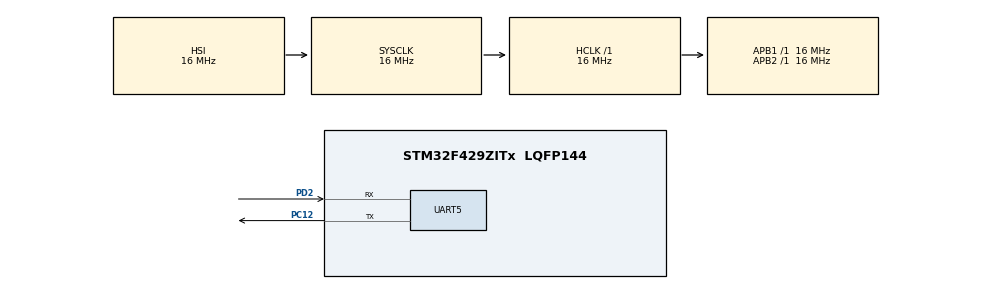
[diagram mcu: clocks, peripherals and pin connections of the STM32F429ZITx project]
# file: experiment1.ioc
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Mcu.Family=STM32F4
RCC.CortexFreq_Value=16000000
PC12.Signal=UART5_TX
PC14/OSC32_IN.Mode=LSE-External-Oscillator
UART5.VirtualMode=Asynchronous
ProjectManager.StackSize=0x400
ProjectManager.TargetToolchain=STM32CubeIDE
PH0/OSC_IN.Mode=HSE-External-Clock-Source
RCC.HCLKFreq_Value=16000000
RCC.APB2TimFreq_Value=16000000
PH1/OSC_OUT.Signal=RCC_OSC_OUT
RCC.AHBFreq_Value=16000000
PD2.Mode=Asynchronous
RCC.HSE_VALUE=25000000
PC12.Mode=Asynchronous
board=custom
RCC.VCOOutputFreq_Value=192000000
PH0/OSC_IN.Signal=RCC_OSC_IN
RCC.APB2Freq_Value=16000000
PH1/OSC_OUT.Mode=HSE-External-Clock-Source
Mcu.Name=STM32F429ZITx
RCC.48MHZClocksFreq_Value=48000000
RCC.SYSCLKFreq_VALUE=16000000
Mcu.Package=LQFP144
PC14/OSC32_IN.Signal=RCC_OSC32_IN
PC15/OSC32_OUT.Mode=LSE-External-Oscillator
ProjectManager.HeapSize=0x200
RCC.HSI_VALUE=16000000
NVIC.PriorityGroup=NVIC_PRIORITYGROUP_4
RCC.APB1TimFreq_Value=16000000
PC15/OSC32_OUT.Signal=RCC_OSC32_OUT
PD2.Signal=UART5_RX
RCC.APB1Freq_Value=16000000

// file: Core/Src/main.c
/* USER CODE BEGIN Header */
/**
  ******************************************************************************
  * @file           : main.c
  * @brief          : Main program body
  ******************************************************************************
  * @attention
  *
  * <h2><center>&copy; Copyright (c) 2021 STMicroelectronics.
  * All rights reserved.</center></h2>
  *
  * This software component is licensed by ST under BSD 3-Clause license,
  * the "License"; You may not use this file except in compliance with the
  * License. You may obtain a copy of the License at:
  *                        opensource.org/licenses/BSD-3-Clause
  *
  ******************************************************************************
  */
/* USER CODE END Header */
#include "main.h"

/* USER CODE BEGIN Includes */
#include "Gpio.h"
#include "RCC.h"
#include "Timer.h"
#include "nvic.h"
/* USER CODE END Includes */

UART_HandleTypeDef huart5;

void SystemClock_Config(void);
static void MX_GPIO_Init(void);
static void MX_UART5_Init(void);

int main(void)
{

  /* MCU Configuration--------------------------------------------------------*/

  /* Reset of all peripherals, Initializes the Flash interface and the Systick. */
  HAL_Init();

  /* Configure the system clock */
  SystemClock_Config();

  /* Initialize all configured peripherals */
  MX_GPIO_Init();
  MX_UART5_Init();
  /* USER CODE BEGIN 2 */
  experiment1();
  /* USER CODE END 2 */

  /* Infinite loop */
  while (1)
  {

  }
}

void SystemClock_Config(void)
{
  RCC_OscInitTypeDef RCC_OscInitStruct = {0};
  RCC_ClkInitTypeDef RCC_ClkInitStruct = {0};

  /** Configure the main internal regulator output voltage
  */
  __HAL_RCC_PWR_CLK_ENABLE();
  __HAL_PWR_VOLTAGESCALING_CONFIG(PWR_REGULATOR_VOLTAGE_SCALE3);
  /** Initializes the RCC Oscillators according to the specified parameters
  * in the RCC_OscInitTypeDef structure.
  */
  RCC_OscInitStruct.OscillatorType = RCC_OSCILLATORTYPE_HSI;
  RCC_OscInitStruct.HSIState = RCC_HSI_ON;
  RCC_OscInitStruct.HSICalibrationValue = RCC_HSICALIBRATION_DEFAULT;
  RCC_OscInitStruct.PLL.PLLState = RCC_PLL_NONE;
  if (HAL_RCC_OscConfig(&RCC_OscInitStruct) != HAL_OK)
  {
    Error_Handler();
  }
  /** Initializes the CPU, AHB and APB buses clocks
  */
  RCC_ClkInitStruct.ClockType = RCC_CLOCKTYPE_HCLK|RCC_CLOCKTYPE_SYSCLK
                              |RCC_CLOCKTYPE_PCLK1|RCC_CLOCKTYPE_PCLK2;
  RCC_ClkInitStruct.SYSCLKSource = RCC_SYSCLKSOURCE_HSI;
  RCC_ClkInitStruct.AHBCLKDivider = RCC_SYSCLK_DIV1;
  RCC_ClkInitStruct.APB1CLKDivider = RCC_HCLK_DIV1;
  RCC_ClkInitStruct.APB2CLKDivider = RCC_HCLK_DIV1;

  if (HAL_RCC_ClockConfig(&RCC_ClkInitStruct, FLASH_LATENCY_0) != HAL_OK)
  {
    Error_Handler();
  }
}

static void MX_UART5_Init(void)
{

  huart5.Instance = UART5;
  huart5.Init.BaudRate = 115200;
  huart5.Init.WordLength = UART_WORDLENGTH_8B;
  huart5.Init.StopBits = UART_STOPBITS_1;
  huart5.Init.Parity = UART_PARITY_NONE;
  huart5.Init.Mode = UART_MODE_TX_RX;
  huart5.Init.HwFlowCtl = UART_HWCONTROL_NONE;
  huart5.Init.OverSampling = UART_OVERSAMPLING_16;
  if (HAL_UART_Init(&huart5) != HAL_OK)
  {
    Error_Handler();
  }

}

static void MX_GPIO_Init(void)
{

  /* GPIO Ports Clock Enable */
  __HAL_RCC_GPIOC_CLK_ENABLE();
  __HAL_RCC_GPIOH_CLK_ENABLE();
  __HAL_RCC_GPIOD_CLK_ENABLE();

}

void Error_Handler(void)
{
  __disable_irq();
  while (1)
  {
  }
}

/************************ (C) COPYRIGHT STMicroelectronics *****END OF FILE****/
